# SF32LB57x register map
File version: 1.0
CPU: CM33 r0p1, little endian, MPU, FPU, 3 interrupt priority bits
Registers are 32-bit, read-write, reset 0x0 unless marked. A register's access mark holds for its fields unless they carry their own. Offsets are from the block's base; [hi:lo] are bit positions; {n}, {i} and the like mark numbered series.

## GPADC
Base 0x500B2000
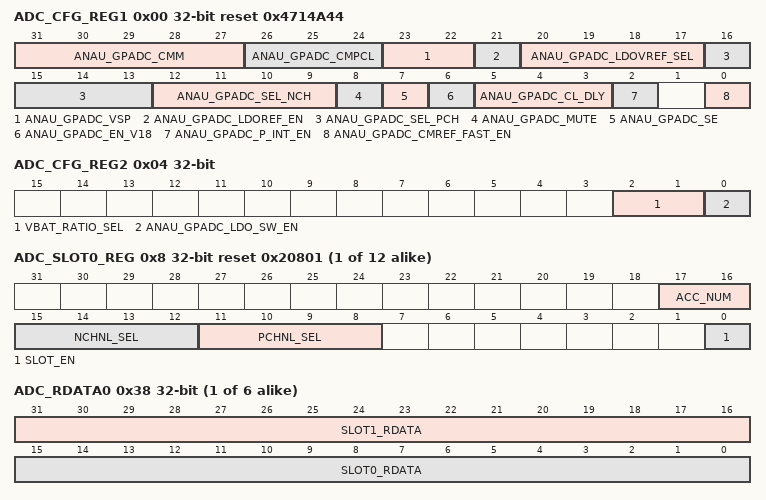
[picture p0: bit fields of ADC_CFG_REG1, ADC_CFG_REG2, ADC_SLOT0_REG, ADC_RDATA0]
0x00 ADC_CFG_REG1 reset 0x4714A44 — ADC Analog Config Register 1
  [31:27] ANAU_GPADC_CMM — Tune CDAC CM voltage 375mV range (increasing) / 25mV step, 8: for 0.5V Vcm,in
  [26:24] ANAU_GPADC_CMPCL — Tune ADC comparator CL= 3: 40f, range: 10fF (0) ~ 80fF (7) / 10fF step
  [23:22] ANAU_GPADC_VSP — Set comparator input CM in sampling phase, 0.539V (0) / 0.578V (1) / 0.642V (2) / 0.784V (3)
  [21] ANAU_GPADC_LDOREF_EN — Enable LDORF for ADC VREF
  [20:17] ANAU_GPADC_LDOVREF_SEL — Set reference voltage for LDOREF, range = 0.35V(0) ~ 0.65V(15), step = 20mV
  [16:13] ANAU_GPADC_SEL_PCH — Select P-side input channel for GPADC, 0 for channel 0, 7 for channel 7, effective when force on
  [12:9] ANAU_GPADC_SEL_NCH — Select N-side input channel for GPADC, 0 for channel 0, 7 for channel 7, effective when force on
  [8] ANAU_GPADC_MUTE — Short GPADC P and N input to CMREF, i.e., VREF/2
  [7] ANAU_GPADC_SE — Set GPADC in single-ended mode, signal range at P-input: 0 ~ VREF
  [6] ANAU_GPADC_EN_V18
  [5:3] ANAU_GPADC_CL_DLY
  [2] ANAU_GPADC_P_INT_EN
  [0] ANAU_GPADC_CMREF_FAST_EN
0x04 ADC_CFG_REG2 — ADC Analog Config Register 2
  [2:1] VBAT_RATIO_SEL — Control the VBAT divide ration for different AVDD and VBAT voltages
  [0] ANAU_GPADC_LDO_SW_EN — Control VREF in case using external VREF(same timing as ANAU_GPADC1_LDOREF_EN_LV)
{0x8+4i} ADC_SLOT{i}_REG reset 0x20801 (i=0..11) — ADC Slot{i} Config Register
  [17:16] ACC_NUM — when slot enabled, measure 2^acc_num times, then output the averaged value
  [15:12] NCHNL_SEL
  [11:8] PCHNL_SEL
  [0] SLOT_EN
{0x38+4i} ADC_RDATA{i} (i=0..5) — ADC Read Data{i}
  [31:16] SLOT{2i+1}_RDATA, [15:0] SLOT{2i}_RDATA
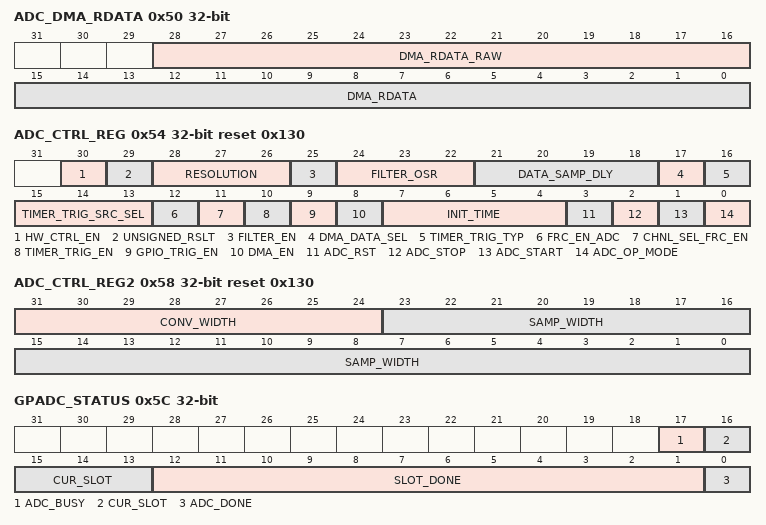
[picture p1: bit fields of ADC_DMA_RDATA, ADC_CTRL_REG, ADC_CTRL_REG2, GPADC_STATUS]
0x50 ADC_DMA_RDATA — ADC Read Data For DMA
  [28:16] DMA_RDATA_RAW, [15:0] DMA_RDATA
0x54 ADC_CTRL_REG reset 0x130 — ADC Control Register
  [30] HW_CTRL_EN — 1. enable hw control of rst and switch signals
  [29] UNSIGNED_RSLT — 0: output is 2's complementary; 1:unsigned output
  [28:26] RESOLUTION — 0:12bit; 1: 13bit; 2:14bit; 3:15bit; 4:16bit
  [25] FILTER_EN — when set to 1 filter is enabled, when set to 0 filter is disabled
  [24:22] FILTER_OSR — filter over sampling rate when FILTER_EN is 1
  [21:18] DATA_SAMP_DLY
  [17] DMA_DATA_SEL — 1: combined data 0: filtered data
  [16] TIMER_TRIG_TYP — 0: pulse no edge detect needed 1: level,need edge detect
  [15:13] TIMER_TRIG_SRC_SEL
  [12] FRC_EN_ADC
  [11] CHNL_SEL_FRC_EN
  [10] TIMER_TRIG_EN
  [9] GPIO_TRIG_EN
  [8] DMA_EN
  [7:4] INIT_TIME
  [3] ADC_RST — write 1 to reset SAR output
  [2] ADC_STOP
  [1] ADC_START
  [0] ADC_OP_MODE — 0: finite 1: inifinite
0x58 ADC_CTRL_REG2 reset 0x130 — ADC Control Register2
  [31:24] CONV_WIDTH, [23:0] SAMP_WIDTH
0x5C GPADC_STATUS
  [17] ADC_BUSY, [16:13] CUR_SLOT, [12:1] SLOT_DONE, [0] ADC_DONE
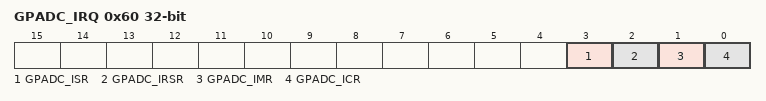
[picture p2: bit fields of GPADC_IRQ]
0x60 GPADC_IRQ
  [3] GPADC_ISR, [2] GPADC_IRSR, [1] GPADC_IMR, [0] GPADC_ICR

## HPSYS_AON
Base 0x500C0000
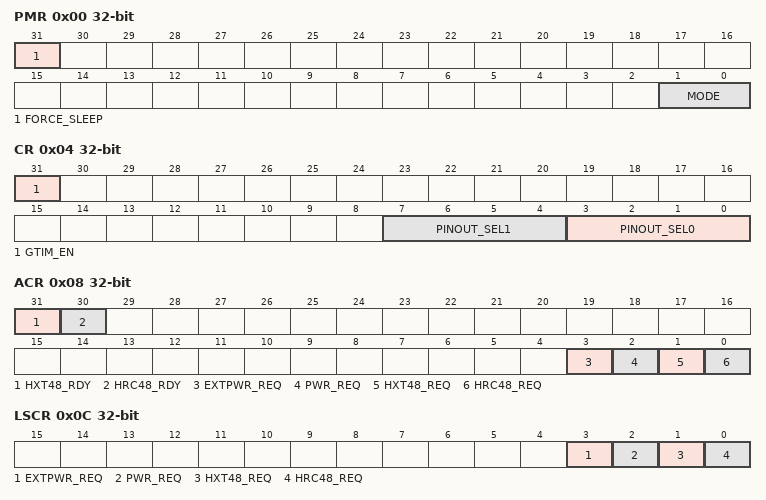
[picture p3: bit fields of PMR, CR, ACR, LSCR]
0x00 PMR — Power Mode Register
  [31] FORCE_SLEEP — force to enter low power mode (for debug only)
  [1:0] MODE — Power Mode: 2'h0 - active/idle; 2'h1 - light sleep; 2'h2 - deep sleep; 2'h3 - standby
0x04 CR — Control Register
  [31] GTIM_EN — Enable global timer
  [7:4] PINOUT_SEL1
  [3:0] PINOUT_SEL0 — Select output signal to VDD_AON. LSB 3-bit valid
0x08 ACR — Active Mode Control register
  [31] HXT48_RDY
  [30] HRC48_RDY
  [3] EXTPWR_REQ — Request power supply for LPSYS upon wakeup. It can help reduce LPSYS wakeup time
  [2] PWR_REQ — Request power supply for HPSYS itself
  [1] HXT48_REQ — Request HXT48 in active mode
  [0] HRC48_REQ — Request HRC48 in active mode
0x0C LSCR — Light Sleep Ctrl Register
  [3] EXTPWR_REQ — Request power for LPSYS during Light Sleep mode
  [2] PWR_REQ — Request power for HPSYS during Light Sleep mode
  [1] HXT48_REQ — Request HXT48 in Light Sleep mode
  [0] HRC48_REQ — Request HRC48 in Light Sleep mode
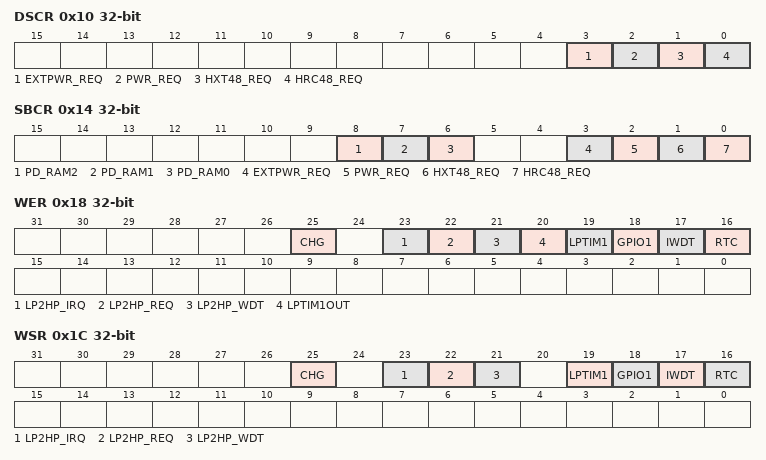
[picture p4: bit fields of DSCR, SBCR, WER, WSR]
0x10 DSCR — Deep Sleep Ctrl Register
  [3] EXTPWR_REQ — Request power for LPSYS during Deep Sleep mode
  [2] PWR_REQ — Request power for HPSYS during Deep Sleep mode
  [1] HXT48_REQ — Request HXT48 in Deep Sleep mode
  [0] HRC48_REQ — Request HRC48 in Deep Sleep mode
0x14 SBCR — Standby Mode Ctrl Register
  [8] PD_RAM2
  [7] PD_RAM1
  [6] PD_RAM0 — Power down RAM0 during Standby Mode
  [3] EXTPWR_REQ — Request power for LPSYS during Standby mode
  [2] PWR_REQ — Request power for HPSYS during Standby mode
  [1] HXT48_REQ — Request HXT48 in Standby mode
  [0] HRC48_REQ — Request HRC48 in Standby mode
0x18 WER — Wakeup Enable register
  [25] CHG — Set 1 to enable CHG as wakeup source
  [23] LP2HP_IRQ
  [22] LP2HP_REQ
  [21] LP2HP_WDT — Set 1 to enable WDT2 2nd timeout as wakeup source
  [20] LPTIM1OUT — Set 1 to enable LPTIM1OUT as periodic wakeup source
  [19] LPTIM1 — Set 1 to enable LPTIM1 as wakeup source
  [18] GPIO1 — Set 1 to enable GPIO1 as wakeup source
  [17] IWDT — Set 1 to enable IWDT as wakeup source
  [16] RTC — Set 1 to enable RTC as wakeup source
0x1C WSR — Wakeup Status register
  [25] CHG — Indicates the wakeup status from CHG. Note: the status is masked by WER
  [23] LP2HP_IRQ
  [22] LP2HP_REQ
  [21] LP2HP_WDT
  [19] LPTIM1 — Indicates the wakeup status from LPTIM1. Note: the status is masked by WER
  [18] GPIO1 — Indicates the wakeup status from GPIO1. Note: the status is masked by WER
  [17] IWDT — Indicates the wakeup status from IWDT. Note: the status is masked by WER
  [16] RTC — Indicates the wakeup status from RTC. Note: the status is masked by WER
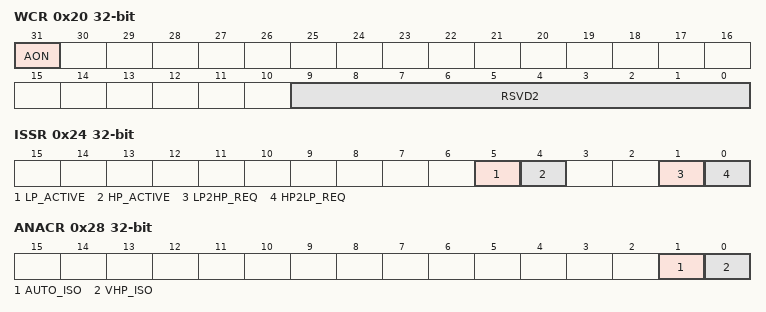
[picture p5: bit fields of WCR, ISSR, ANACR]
0x20 WCR — Wakeup Clear register
  [31] AON — Write 1 to clear the AON wakeup IRQ status
  [9:0] RSVD2 — Note: clear the wakeup status directly in the orignal module
0x24 ISSR — Inter System Wakeup Register
  [5] LP_ACTIVE — 1 indicates LP system is active
  [4] HP_ACTIVE
  [1] LP2HP_REQ
  [0] HP2LP_REQ — Set REQ bit and wait for several cycles, then check LP active status. It forces LP to stay in active mode
0x28 ANACR — Analog Control Register
  [1] AUTO_ISO
  [0] VHP_ISO — Set 1 to force off all HPSYS related analog modules, including USB/DSI/DLL etc
0x2C GTIMR — Global Timer Register
  [31:0] CNT — Global timer value. Write to restart from 0 and sync both HP and LP sides
0x30 RESERVE0 — Reserve Register 0
  [31:0] DATA
0x34 RESERVE1 — Reserve Register 1
  [31:0] DATA
